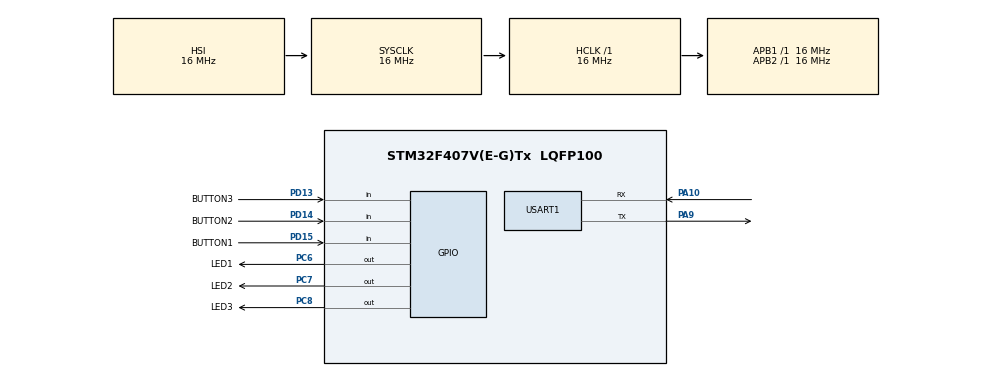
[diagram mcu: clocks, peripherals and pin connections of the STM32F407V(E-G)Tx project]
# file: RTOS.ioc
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FREERTOS.Tasks01=defaultTask,0,128,StartDefaultTask,Default,NULL
Mcu.Family=STM32F4
Mcu.Name=STM32F407V(E-G)Tx
Mcu.Package=LQFP100
NVIC.PriorityGroup=NVIC_PRIORITYGROUP_4
PA10.Mode=Asynchronous
PA10.Signal=USART1_RX
PA9.Mode=Asynchronous
PA9.Signal=USART1_TX
PC6.GPIO_Label=LED1
PC6.Signal=GPIO_Output
PC7.GPIO_Label=LED2
PC7.Signal=GPIO_Output
PC8.GPIO_Label=LED3
PC8.Signal=GPIO_Output
PD13.GPIO_Label=BUTTON3
PD13.Signal=GPIO_Input
PD14.GPIO_Label=BUTTON2
PD14.Signal=GPIO_Input
PD15.GPIO_Label=BUTTON1
PD15.Signal=GPIO_Input
ProjectManager.HeapSize=0x200
ProjectManager.StackSize=0x400
ProjectManager.TargetToolchain=MDK-ARM V5
RCC.AHBFreq_Value=16000000
RCC.APB1Freq_Value=16000000
RCC.APB2Freq_Value=16000000
RCC.CortexFreq_Value=16000000
RCC.HSE_VALUE=25000000
RCC.HSI_VALUE=16000000
RCC.LSE_VALUE=32768
RCC.SYSCLKFreq_VALUE=16000000
RCC.VCOOutputFreq_Value=192000000
USART1.VirtualMode=VM_ASYNC
VP_FREERTOS_VS_ENABLE.Mode=Enabled
board=custom

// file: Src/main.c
/**
  ******************************************************************************
  * @file           : main.c
  * @brief          : Main program body
  ******************************************************************************
  * This notice applies to any and all portions of this file
  * that are not between comment pairs USER CODE BEGIN and
  * USER CODE END. Other portions of this file, whether
  * inserted by the user or by software development tools
  * are owned by their respective copyright owners.
  *
  * Copyright (c) 2018 STMicroelectronics International N.V.
  * All rights reserved.
  *
  * Redistribution and use in source and binary forms, with or without
  * modification, are permitted, provided that the following conditions are met:
  *
  * 1. Redistribution of source code must retain the above copyright notice,
  *    this list of conditions and the following disclaimer.
  * 2. Redistributions in binary form must reproduce the above copyright notice,
  *    this list of conditions and the following disclaimer in the documentation
  *    and/or other materials provided with the distribution.
  * 3. Neither the name of STMicroelectronics nor the names of other
  *    contributors to this software may be used to endorse or promote products
  *    derived from this software without specific written permission.
  * 4. This software, including modifications and/or derivative works of this
  *    software, must execute solely and exclusively on microcontroller or
  *    microprocessor devices manufactured by or for STMicroelectronics.
  * 5. Redistribution and use of this software other than as permitted under
  *    this license is void and will automatically terminate your rights under
  *    this license.
  *
  * THIS SOFTWARE IS PROVIDED BY STMICROELECTRONICS AND CONTRIBUTORS "AS IS"
  * AND ANY EXPRESS, IMPLIED OR STATUTORY WARRANTIES, INCLUDING, BUT NOT
  * LIMITED TO, THE IMPLIED WARRANTIES OF MERCHANTABILITY, FITNESS FOR A
  * PARTICULAR PURPOSE AND NON-INFRINGEMENT OF THIRD PARTY INTELLECTUAL PROPERTY
  * RIGHTS ARE DISCLAIMED TO THE FULLEST EXTENT PERMITTED BY LAW. IN NO EVENT
  * SHALL STMICROELECTRONICS OR CONTRIBUTORS BE LIABLE FOR ANY DIRECT, INDIRECT,
  * INCIDENTAL, SPECIAL, EXEMPLARY, OR CONSEQUENTIAL DAMAGES (INCLUDING, BUT NOT
  * LIMITED TO, PROCUREMENT OF SUBSTITUTE GOODS OR SERVICES; LOSS OF USE, DATA,
  * OR PROFITS; OR BUSINESS INTERRUPTION) HOWEVER CAUSED AND ON ANY THEORY OF
  * LIABILITY, WHETHER IN CONTRACT, STRICT LIABILITY, OR TORT (INCLUDING
  * NEGLIGENCE OR OTHERWISE) ARISING IN ANY WAY OUT OF THE USE OF THIS SOFTWARE,
  * EVEN IF ADVISED OF THE POSSIBILITY OF SUCH DAMAGE.
  *
  ******************************************************************************
  */
#include "main.h"
#include "stm32f4xx_hal.h"
#include "cmsis_os.h"

UART_HandleTypeDef huart1;

osThreadId defaultTaskHandle;

/* USER CODE BEGIN PV */
/* Private variables ---------------------------------------------------------*/

/* USER CODE END PV */

void SystemClock_Config(void);
static void MX_GPIO_Init(void);
static void MX_USART1_UART_Init(void);
void StartDefaultTask(void const * argument);
static void prvOneShotTimerCallback( TimerHandle_t xTimer );
static void prvAutoReloadTimerCallback( TimerHandle_t xTimer );

/* USER CODE BEGIN PFP */
/* Private function prototypes -----------------------------------------------*/
#ifdef __GNUC__
  /* With GCC/RAISONANCE, small printf (option LD Linker->Libraries->Small printf
     set to 'Yes') calls __io_putchar() */
  #define PUTCHAR_PROTOTYPE int __io_putchar(int ch)
#else
  #define PUTCHAR_PROTOTYPE int fputc(int ch, FILE *f)
#endif /* __GNUC__ */

/**
  * @brief  Retargets the C library printf function to the USART.
  * @param  None
  * @retval None
  */
PUTCHAR_PROTOTYPE
{
    /* Place your implementation of fputc here */
    /* e.g. write a character to the USART */
    HAL_UART_Transmit(&huart1, (uint8_t *)&ch, 1, 100);

    return ch;
}
/* USER CODE END PFP */

BaseType_t ulCallCount = 0;

/* USER CODE BEGIN 0 */
/* The periods assigned to the one-shot and auto-reload timers are 3.333 second and half a
second respectively. */
#define mainONE_SHOT_TIMER_PERIOD		pdMS_TO_TICKS( 3333 )
#define mainAUTO_RELOAD_TIMER_PERIOD	pdMS_TO_TICKS( 500 )
/* USER CODE END 0 */

int main(void)
{
  /* USER CODE BEGIN 1 */
	TimerHandle_t xAutoReloadTimer, xOneShotTimer;
	BaseType_t xTimer1Started, xTimer2Started;
  /* USER CODE END 1 */

  /* MCU Configuration----------------------------------------------------------*/

  /* Reset of all peripherals, Initializes the Flash interface and the Systick. */
  HAL_Init();

  /* Configure the system clock */
  SystemClock_Config();

  /* Initialize all configured peripherals */
  MX_GPIO_Init();
  MX_USART1_UART_Init();
  /* USER CODE BEGIN 2 */
	/* Create the one shot timer, storing the handle to the created timer in xOneShotTimer. */
	xOneShotTimer = xTimerCreate(
					/* Text name for the software timer - not used by FreeRTOS. */
					"OneShot",
					/* The software timer's period in ticks. */
					mainONE_SHOT_TIMER_PERIOD,
					/* Setting uxAutoReload to pdFALSE creates a one-shot software timer. */
					pdFALSE,
					/* This exampole does not use the timer id. */
					0,
					/* The callback function to be used by the software timer being created. */
					prvOneShotTimerCallback);

	/* Create the auto-reload timer, storing the handle to the created timer in xAutoReloadTimer. */
	xAutoReloadTimer = xTimerCreate(
					/* Text name for the software timer - not used by FreeRTOS. */
					"AutoReload",
					/* The software timer's period in ticks. */
					mainAUTO_RELOAD_TIMER_PERIOD,
					/* Setting uxAutoReload to pdTRUE creates an auto-reload timer. */
					pdTRUE,
					/* This example does not use the timer id. */
					0,
					/* The callback function to be used by the software timer being created. */
					prvAutoReloadTimerCallback);

	/* Check the software timers were created. */
	if( ( xOneShotTimer != NULL ) && (xAutoReloadTimer != NULL) )
	{
		/* Start the software timers, using a block time of 0 (no block time). The scheduler has
		not been started yet so any block time specified here would be ignored anyway. */
		xTimer1Started = xTimerStart( xOneShotTimer, 0 );
		xTimer2Started = xTimerStart( xAutoReloadTimer, 0 );

		/* The implementation of xTimerStart() uses the timer command queue, and xTimerStart()
		will fail if the timer command queue gets full. The timer service task does not get
		created until the scheduler is started, so all commands sent to the command queue will
		stay in the queue until after the scheduler has been started. Check both calls to
		xTimerStart() passed. */
		if( ( xTimer1Started == pdPASS ) && ( xTimer2Started == pdPASS ) )
		{
			/* Start the scheduler. */
			vTaskStartScheduler();
		}
	}

  while (1)
  {

  }

}

static void prvOneShotTimerCallback( TimerHandle_t xTimer )
{
	TickType_t xTimeNow;

	/* Obtain the current tick count. */
	xTimeNow = xTaskGetTickCount();

	/* Output a string to show the time at which the callback was executed. */
	printf("One-shot timer callback executing %d\r\n", xTimeNow);

	/* File scope variable. */
	ulCallCount++;
}

static void prvAutoReloadTimerCallback( TimerHandle_t xTimer )
{
	TickType_t xTimeNow;

	/* Obtain the current tick count. */
	xTimeNow = xTaskGetTickCount();

	/* Output a string to show the time at which the callback was executed. */
	printf("Auto-reload timer callback executing %d\r\n", xTimeNow);

	/* File scope variable. */
	ulCallCount++;
}

void SystemClock_Config(void)
{

  RCC_OscInitTypeDef RCC_OscInitStruct;
  RCC_ClkInitTypeDef RCC_ClkInitStruct;

    /**Configure the main internal regulator output voltage
    */
  __HAL_RCC_PWR_CLK_ENABLE();

  __HAL_PWR_VOLTAGESCALING_CONFIG(PWR_REGULATOR_VOLTAGE_SCALE1);

    /**Initializes the CPU, AHB and APB busses clocks
    */
  RCC_OscInitStruct.OscillatorType = RCC_OSCILLATORTYPE_HSI;
  RCC_OscInitStruct.HSIState = RCC_HSI_ON;
  RCC_OscInitStruct.HSICalibrationValue = 16;
  RCC_OscInitStruct.PLL.PLLState = RCC_PLL_NONE;
  if (HAL_RCC_OscConfig(&RCC_OscInitStruct) != HAL_OK)
  {
    _Error_Handler(__FILE__, __LINE__);
  }

    /**Initializes the CPU, AHB and APB busses clocks
    */
  RCC_ClkInitStruct.ClockType = RCC_CLOCKTYPE_HCLK|RCC_CLOCKTYPE_SYSCLK
                              |RCC_CLOCKTYPE_PCLK1|RCC_CLOCKTYPE_PCLK2;
  RCC_ClkInitStruct.SYSCLKSource = RCC_SYSCLKSOURCE_HSI;
  RCC_ClkInitStruct.AHBCLKDivider = RCC_SYSCLK_DIV1;
  RCC_ClkInitStruct.APB1CLKDivider = RCC_HCLK_DIV1;
  RCC_ClkInitStruct.APB2CLKDivider = RCC_HCLK_DIV1;

  if (HAL_RCC_ClockConfig(&RCC_ClkInitStruct, FLASH_LATENCY_0) != HAL_OK)
  {
    _Error_Handler(__FILE__, __LINE__);
  }

    /**Configure the Systick interrupt time
    */
  HAL_SYSTICK_Config(HAL_RCC_GetHCLKFreq()/1000);

    /**Configure the Systick
    */
  HAL_SYSTICK_CLKSourceConfig(SYSTICK_CLKSOURCE_HCLK);

  /* SysTick_IRQn interrupt configuration */
  HAL_NVIC_SetPriority(SysTick_IRQn, 15, 0);
}

/* USART1 init function */
static void MX_USART1_UART_Init(void)
{

  huart1.Instance = USART1;
  huart1.Init.BaudRate = 115200;
  huart1.Init.WordLength = UART_WORDLENGTH_8B;
  huart1.Init.StopBits = UART_STOPBITS_1;
  huart1.Init.Parity = UART_PARITY_NONE;
  huart1.Init.Mode = UART_MODE_TX_RX;
  huart1.Init.HwFlowCtl = UART_HWCONTROL_NONE;
  huart1.Init.OverSampling = UART_OVERSAMPLING_16;
  if (HAL_UART_Init(&huart1) != HAL_OK)
  {
    _Error_Handler(__FILE__, __LINE__);
  }

}

/** Configure pins as
        * Analog
        * Input
        * Output
        * EVENT_OUT
        * EXTI
*/
static void MX_GPIO_Init(void)
{

  GPIO_InitTypeDef GPIO_InitStruct;

  /* GPIO Ports Clock Enable */
  __HAL_RCC_GPIOD_CLK_ENABLE();
  __HAL_RCC_GPIOC_CLK_ENABLE();
  __HAL_RCC_GPIOA_CLK_ENABLE();

  /*Configure GPIO pin Output Level */
  HAL_GPIO_WritePin(GPIOC, LED1_Pin|LED2_Pin|LED3_Pin, GPIO_PIN_RESET);

  /*Configure GPIO pins : BUTTON3_Pin BUTTON2_Pin BUTTON1_Pin */
  GPIO_InitStruct.Pin = BUTTON3_Pin|BUTTON2_Pin|BUTTON1_Pin;
  GPIO_InitStruct.Mode = GPIO_MODE_INPUT;
  GPIO_InitStruct.Pull = GPIO_NOPULL;
  HAL_GPIO_Init(GPIOD, &GPIO_InitStruct);

  /*Configure GPIO pins : LED1_Pin LED2_Pin LED3_Pin */
  GPIO_InitStruct.Pin = LED1_Pin|LED2_Pin|LED3_Pin;
  GPIO_InitStruct.Mode = GPIO_MODE_OUTPUT_PP;
  GPIO_InitStruct.Pull = GPIO_NOPULL;
  GPIO_InitStruct.Speed = GPIO_SPEED_FREQ_LOW;
  HAL_GPIO_Init(GPIOC, &GPIO_InitStruct);

}

void StartDefaultTask(void const * argument)
{

  for(;;)
  {
    osDelay(1);
  }
}

void _Error_Handler(char *file, int line)
{
  while(1)
  {
  }
}

/************************ (C) COPYRIGHT STMicroelectronics *****END OF FILE****/
